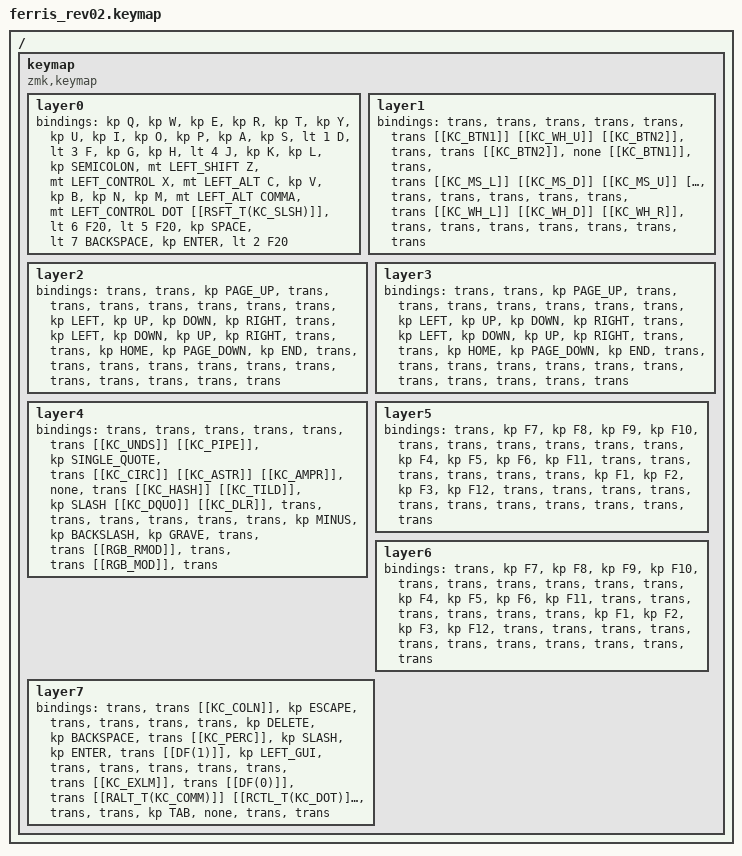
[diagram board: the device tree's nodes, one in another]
  /*
  * Copyright (c) 2020 The ZMK Contributors
  *
  * SPDX-License-Identifier: MIT
  */

  #include <behaviors.dtsi>
  #include <dt-bindings/zmk/keys.h>
  #include <dt-bindings/zmk/bt.h>
  #include <dt-bindings/zmk/ext_power.h>
  / {
    keymap {
      compatible = "zmk,keymap";
  layer0 {
          bindings = <
          &kp Q &kp W &kp E &kp R &kp T &kp Y &kp U &kp I &kp O &kp P &kp A &kp S &lt 1 D &lt 3 F &kp G &kp H &lt 4 J &kp K &kp L &kp SEMICOLON &mt LEFT_SHIFT Z &mt LEFT_CONTROL X &mt LEFT_ALT C &kp V &kp B &kp N &kp M &mt LEFT_ALT COMMA &mt LEFT_CONTROL DOT [[RSFT_T(KC_SLSH)]] &lt 6 F20 &lt 5 F20 &kp SPACE &lt 7 BACKSPACE &kp ENTER &lt 2 F20
          >;
        };layer1 {
          bindings = <
          &trans &trans &trans &trans &trans &trans [[KC_BTN1]] [[KC_WH_U]] [[KC_BTN2]] &trans &trans [[KC_BTN2]] &none [[KC_BTN1]] &trans &trans [[KC_MS_L]] [[KC_MS_D]] [[KC_MS_U]] [[KC_MS_R]] &trans &trans &trans &trans &trans &trans [[KC_WH_L]] [[KC_WH_D]] [[KC_WH_R]] &trans &trans &trans &trans &trans &trans &trans
          >;
        };layer2 {
          bindings = <
          &trans &trans &kp PAGE_UP &trans &trans &trans &trans &trans &trans &trans &kp LEFT &kp UP &kp DOWN &kp RIGHT &trans &kp LEFT &kp DOWN &kp UP &kp RIGHT &trans &trans &kp HOME &kp PAGE_DOWN &kp END &trans &trans &trans &trans &trans &trans &trans &trans &trans &trans &trans &trans
          >;
        };layer3 {
          bindings = <
          &trans &trans &kp PAGE_UP &trans &trans &trans &trans &trans &trans &trans &kp LEFT &kp UP &kp DOWN &kp RIGHT &trans &kp LEFT &kp DOWN &kp UP &kp RIGHT &trans &trans &kp HOME &kp PAGE_DOWN &kp END &trans &trans &trans &trans &trans &trans &trans &trans &trans &trans &trans &trans
          >;
        };layer4 {
          bindings = <
          &trans &trans &trans &trans &trans &trans [[KC_UNDS]] [[KC_PIPE]] &kp SINGLE_QUOTE &trans [[KC_CIRC]] [[KC_ASTR]] [[KC_AMPR]] &none &trans [[KC_HASH]] [[KC_TILD]] &kp SLASH [[KC_DQUO]] [[KC_DLR]] &trans &trans &trans &trans &trans &trans &kp MINUS &kp BACKSLASH &kp GRAVE &trans &trans [[RGB_RMOD]] &trans &trans [[RGB_MOD]] &trans
          >;
        };layer5 {
          bindings = <
          &trans &kp F7 &kp F8 &kp F9 &kp F10 &trans &trans &trans &trans &trans &trans &kp F4 &kp F5 &kp F6 &kp F11 &trans &trans &trans &trans &trans &trans &kp F1 &kp F2 &kp F3 &kp F12 &trans &trans &trans &trans &trans &trans &trans &trans &trans &trans &trans
          >;
        };layer6 {
          bindings = <
          &trans &kp F7 &kp F8 &kp F9 &kp F10 &trans &trans &trans &trans &trans &trans &kp F4 &kp F5 &kp F6 &kp F11 &trans &trans &trans &trans &trans &trans &kp F1 &kp F2 &kp F3 &kp F12 &trans &trans &trans &trans &trans &trans &trans &trans &trans &trans &trans
          >;
        };layer7 {
          bindings = <
          &trans &trans [[KC_COLN]] &kp ESCAPE &trans &trans &trans &trans &kp DELETE &kp BACKSPACE &trans [[KC_PERC]] &kp SLASH &kp ENTER &trans [[DF(1)]] &kp LEFT_GUI &trans &trans &trans &trans &trans &trans [[KC_EXLM]] &trans [[DF(0)]] &trans [[RALT_T(KC_COMM)]] [[RCTL_T(KC_DOT)]] [[QK_BOOT]] &trans &trans &kp TAB &none &trans &trans
          >;
        };
    };
  };
  
